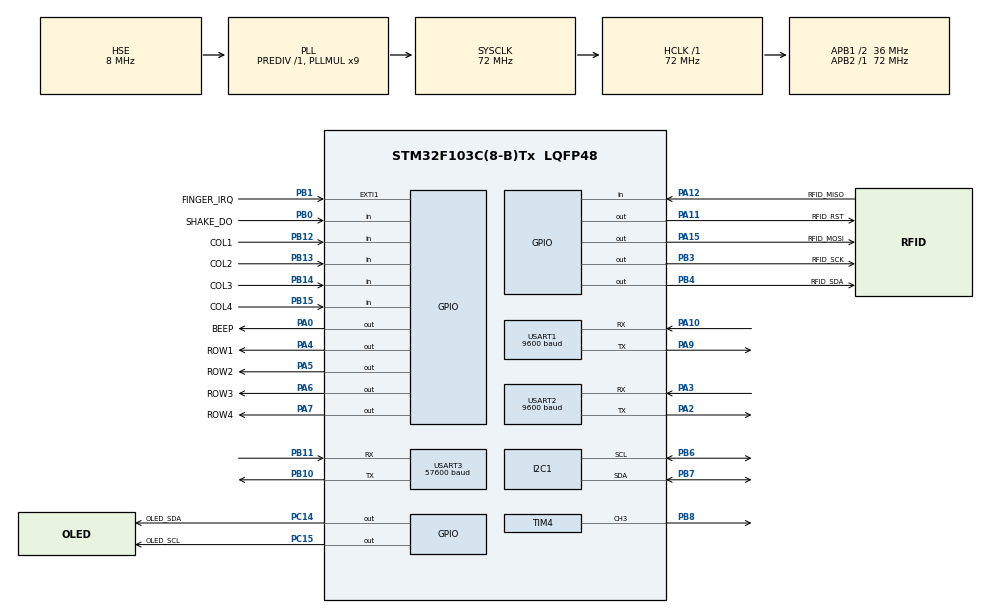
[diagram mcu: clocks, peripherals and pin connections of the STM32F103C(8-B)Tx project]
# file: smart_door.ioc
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FREERTOS.Tasks01=defaultTask,1,256,StartDefaultTask,Default,NULL,Dynamic,NULL,NULL
FREERTOS.configTOTAL_HEAP_SIZE=9216
Mcu.Family=STM32F1
Mcu.Name=STM32F103C(8-B)Tx
Mcu.Package=LQFP48
NVIC.EXTI1_IRQn=true\:5\:0\:false\:false\:true\:true\:true\:true\:true
NVIC.PriorityGroup=NVIC_PRIORITYGROUP_4
NVIC.USART1_IRQn=true\:5\:0\:false\:false\:true\:true\:true\:true\:true
NVIC.USART2_IRQn=true\:5\:0\:false\:false\:true\:true\:true\:true\:true
NVIC.USART3_IRQn=true\:5\:0\:false\:false\:true\:true\:true\:true\:true
PA0-WKUP.GPIO_Label=BEEP
PA0-WKUP.GPIO_PuPd=GPIO_NOPULL
PA0-WKUP.GPIO_Speed=GPIO_SPEED_FREQ_HIGH
PA0-WKUP.PinState=GPIO_PIN_SET
PA0-WKUP.Signal=GPIO_Output
PA10.GPIO_PuPd=GPIO_PULLUP
PA10.Mode=Asynchronous
PA10.Signal=USART1_RX
PA11.GPIO_Label=RFID_RST
PA11.GPIO_Speed=GPIO_SPEED_FREQ_HIGH
PA11.PinState=GPIO_PIN_SET
PA11.Signal=GPIO_Output
PA12.GPIO_Label=RFID_MISO
PA12.GPIO_PuPd=GPIO_PULLUP
PA12.Signal=GPIO_Input
PA13.Mode=Serial_Wire
PA13.Signal=SYS_JTMS-SWDIO
PA14.Mode=Serial_Wire
PA14.Signal=SYS_JTCK-SWCLK
PA15.GPIO_Label=RFID_MOSI
PA15.GPIO_Speed=GPIO_SPEED_FREQ_HIGH
PA15.PinState=GPIO_PIN_SET
PA15.Signal=GPIO_Output
PA2.Mode=Asynchronous
PA2.Signal=USART2_TX
PA3.GPIO_PuPd=GPIO_PULLUP
PA3.Mode=Asynchronous
PA3.Signal=USART2_RX
PA4.GPIO_Label=ROW1
PA4.GPIO_Speed=GPIO_SPEED_FREQ_HIGH
PA4.PinState=GPIO_PIN_SET
PA4.Signal=GPIO_Output
PA5.GPIO_Label=ROW2
PA5.GPIO_Speed=GPIO_SPEED_FREQ_HIGH
PA5.PinState=GPIO_PIN_SET
PA5.Signal=GPIO_Output
PA6.GPIO_Label=ROW3
PA6.GPIO_Speed=GPIO_SPEED_FREQ_HIGH
PA6.PinState=GPIO_PIN_SET
PA6.Signal=GPIO_Output
PA7.GPIO_Label=ROW4
PA7.GPIO_PuPd=GPIO_NOPULL
PA7.GPIO_Speed=GPIO_SPEED_FREQ_HIGH
PA7.PinState=GPIO_PIN_SET
PA7.Signal=GPIO_Output
PA9.Mode=Asynchronous
PA9.Signal=USART1_TX
PB0.GPIO_Label=SHAKE_DO
PB0.Signal=GPIO_Input
PB1.GPIO_Label=FINGER_IRQ
PB1.GPIO_PuPd=GPIO_PULLDOWN
PB1.Signal=GPXTI1
PB10.Mode=Asynchronous
PB10.Signal=USART3_TX
PB11.GPIO_PuPd=GPIO_PULLUP
PB11.Mode=Asynchronous
PB11.Signal=USART3_RX
PB12.GPIO_Label=COL1
PB12.GPIO_PuPd=GPIO_PULLUP
PB12.Signal=GPIO_Input
PB13.GPIO_Label=COL2
PB13.GPIO_PuPd=GPIO_PULLUP
PB13.Signal=GPIO_Input
PB14.GPIO_Label=COL3
PB14.GPIO_PuPd=GPIO_PULLUP
PB14.Signal=GPIO_Input
PB15.GPIO_Label=COL4
PB15.GPIO_PuPd=GPIO_PULLUP
PB15.Signal=GPIO_Input
PB3.GPIO_Label=RFID_SCK
PB3.GPIO_Speed=GPIO_SPEED_FREQ_HIGH
PB3.PinState=GPIO_PIN_SET
PB3.Signal=GPIO_Output
PB4.GPIO_Label=RFID_SDA
PB4.GPIO_Speed=GPIO_SPEED_FREQ_HIGH
PB4.PinState=GPIO_PIN_SET
PB4.Signal=GPIO_Output
PB6.Mode=I2C
PB6.Signal=I2C1_SCL
PB7.Mode=I2C
PB7.Signal=I2C1_SDA
PB8.Signal=S_TIM4_CH3
PC14-OSC32_IN.GPIO_Label=OLED_SDA
PC14-OSC32_IN.GPIO_ModeDefaultOutputPP=GPIO_MODE_OUTPUT_OD
PC14-OSC32_IN.GPIO_PuPd=GPIO_PULLUP
PC14-OSC32_IN.GPIO_Speed=GPIO_SPEED_FREQ_LOW
PC14-OSC32_IN.PinState=GPIO_PIN_SET
PC14-OSC32_IN.Signal=GPIO_Output
PC15-OSC32_OUT.GPIO_Label=OLED_SCL
PC15-OSC32_OUT.GPIO_ModeDefaultOutputPP=GPIO_MODE_OUTPUT_OD
PC15-OSC32_OUT.GPIO_PuPd=GPIO_PULLUP
PC15-OSC32_OUT.GPIO_Speed=GPIO_SPEED_FREQ_LOW
PC15-OSC32_OUT.PinState=GPIO_PIN_SET
PC15-OSC32_OUT.Signal=GPIO_Output
PD0-OSC_IN.Mode=HSE-External-Oscillator
PD0-OSC_IN.Signal=RCC_OSC_IN
PD1-OSC_OUT.Mode=HSE-External-Oscillator
PD1-OSC_OUT.Signal=RCC_OSC_OUT
ProjectManager.HeapSize=0x200
ProjectManager.StackSize=0x400
ProjectManager.TargetToolchain=MDK-ARM V5.32
RCC.AHBFreq_Value=72000000
RCC.APB1CLKDivider=RCC_HCLK_DIV2
RCC.APB1Freq_Value=36000000
RCC.APB1TimFreq_Value=72000000
RCC.APB2Freq_Value=72000000
RCC.APB2TimFreq_Value=72000000
RCC.HCLKFreq_Value=72000000
RCC.PLLMUL=RCC_PLL_MUL9
RCC.PLLSourceVirtual=RCC_PLLSOURCE_HSE
RCC.SYSCLKFreq_VALUE=72000000
RCC.SYSCLKSource=RCC_SYSCLKSOURCE_PLLCLK
RCC.USBFreq_Value=72000000
SH.S_TIM4_CH3.0=TIM4_CH3,PWM Generation3 CH3
TIM4.Channel-PWM\ Generation3\ CH3=TIM_CHANNEL_3
TIM4.Period=20000 - 1
TIM4.Prescaler=72-1
USART1.BaudRate=9600
USART1.VirtualMode=VM_ASYNC
USART2.BaudRate=9600
USART2.VirtualMode=VM_ASYNC
USART3.BaudRate=57600
USART3.VirtualMode=VM_ASYNC
VP_FREERTOS_VS_CMSIS_V2.Mode=CMSIS_V2
board=custom

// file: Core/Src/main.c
/* USER CODE BEGIN Header */
/**
  ******************************************************************************
  * @file           : main.c
  * @brief          : Main program body
  ******************************************************************************
  * @attention
  *
  * <h2><center>&copy; Copyright (c) 2026 STMicroelectronics.
  * All rights reserved.</center></h2>
  *
  * This software component is licensed by ST under BSD 3-Clause license,
  * the "License"; You may not use this file except in compliance with the
  * License. You may obtain a copy of the License at:
  *                        opensource.org/licenses/BSD-3-Clause
  *
  ******************************************************************************
  */
/* USER CODE END Header */
#include "main.h"
#include "cmsis_os.h"
#include "i2c.h"
#include "tim.h"
#include "usart.h"
#include "gpio.h"

void SystemClock_Config(void);
void MX_FREERTOS_Init(void);

int main(void)
{

  /* MCU Configuration--------------------------------------------------------*/

  /* Reset of all peripherals, Initializes the Flash interface and the Systick. */
  HAL_Init();

  /* Configure the system clock */
  SystemClock_Config();

  /* Initialize all configured peripherals */
  MX_GPIO_Init();
  MX_I2C1_Init();
  MX_TIM4_Init();
  MX_USART1_UART_Init();
  MX_USART2_UART_Init();
  MX_USART3_UART_Init();

  /* Init scheduler */
  osKernelInitialize();  /* Call init function for freertos objects (in cmsis_os2.c) */
  MX_FREERTOS_Init();

  /* Start scheduler */
  osKernelStart();

  /* We should never get here as control is now taken by the scheduler */

  /* Infinite loop */
	while (1)
  {

  }
}

void SystemClock_Config(void)
{
  RCC_OscInitTypeDef RCC_OscInitStruct = {0};
  RCC_ClkInitTypeDef RCC_ClkInitStruct = {0};

  /** Initializes the RCC Oscillators according to the specified parameters
  * in the RCC_OscInitTypeDef structure.
  */
  RCC_OscInitStruct.OscillatorType = RCC_OSCILLATORTYPE_HSE;
  RCC_OscInitStruct.HSEState = RCC_HSE_ON;
  RCC_OscInitStruct.HSEPredivValue = RCC_HSE_PREDIV_DIV1;
  RCC_OscInitStruct.HSIState = RCC_HSI_ON;
  RCC_OscInitStruct.PLL.PLLState = RCC_PLL_ON;
  RCC_OscInitStruct.PLL.PLLSource = RCC_PLLSOURCE_HSE;
  RCC_OscInitStruct.PLL.PLLMUL = RCC_PLL_MUL9;
  if (HAL_RCC_OscConfig(&RCC_OscInitStruct) != HAL_OK)
  {
    Error_Handler();
  }

  /** Initializes the CPU, AHB and APB buses clocks
  */
  RCC_ClkInitStruct.ClockType = RCC_CLOCKTYPE_HCLK|RCC_CLOCKTYPE_SYSCLK
                              |RCC_CLOCKTYPE_PCLK1|RCC_CLOCKTYPE_PCLK2;
  RCC_ClkInitStruct.SYSCLKSource = RCC_SYSCLKSOURCE_PLLCLK;
  RCC_ClkInitStruct.AHBCLKDivider = RCC_SYSCLK_DIV1;
  RCC_ClkInitStruct.APB1CLKDivider = RCC_HCLK_DIV2;
  RCC_ClkInitStruct.APB2CLKDivider = RCC_HCLK_DIV1;

  if (HAL_RCC_ClockConfig(&RCC_ClkInitStruct, FLASH_LATENCY_2) != HAL_OK)
  {
    Error_Handler();
  }
}

void Error_Handler(void)
{
  __disable_irq();
  while (1)
  {
  }
}

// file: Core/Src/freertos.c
/* USER CODE BEGIN Header */
/**
  ******************************************************************************
  * File Name          : freertos.c
  * Description        : Code for freertos applications
  ******************************************************************************
  * @attention
  *
  * Copyright (c) 2026 STMicroelectronics.
  * All rights reserved.
  *
  * This software is licensed under terms that can be found in the LICENSE file
  * in the root directory of this software component.
  * If no LICENSE file comes with this software, it is provided AS-IS.
  *
  ******************************************************************************
  */
/* USER CODE END Header */

#include "FreeRTOS.h"
#include "task.h"
#include "main.h"
#include "cmsis_os.h"

/* USER CODE BEGIN Includes */
#include "app.h"
#include "oled.h"
/* USER CODE END Includes */

/* Definitions for defaultTask */
osThreadId_t defaultTaskHandle;
const osThreadAttr_t defaultTask_attributes = {
  .name = "defaultTask",
  .stack_size = 256 * 4,
  .priority = (osPriority_t) osPriorityIdle,
};

void StartDefaultTask(void *argument);

void MX_FREERTOS_Init(void); /* (MISRA C 2004 rule 8.1) */

void MX_FREERTOS_Init(void) {

  /* Create the thread(s) */
  /* creation of defaultTask */
  defaultTaskHandle = osThreadNew(StartDefaultTask, NULL, &defaultTask_attributes);

  /* USER CODE BEGIN RTOS_THREADS */
  configASSERT(defaultTaskHandle != NULL);
  /* add threads, ... */
  App_CreateTasks();
  /* USER CODE END RTOS_THREADS */

}

void StartDefaultTask(void *argument)
{
  /* USER CODE BEGIN StartDefaultTask */
  /* Infinite loop */
  OLED_Task(argument);
  /* USER CODE END StartDefaultTask */
}
